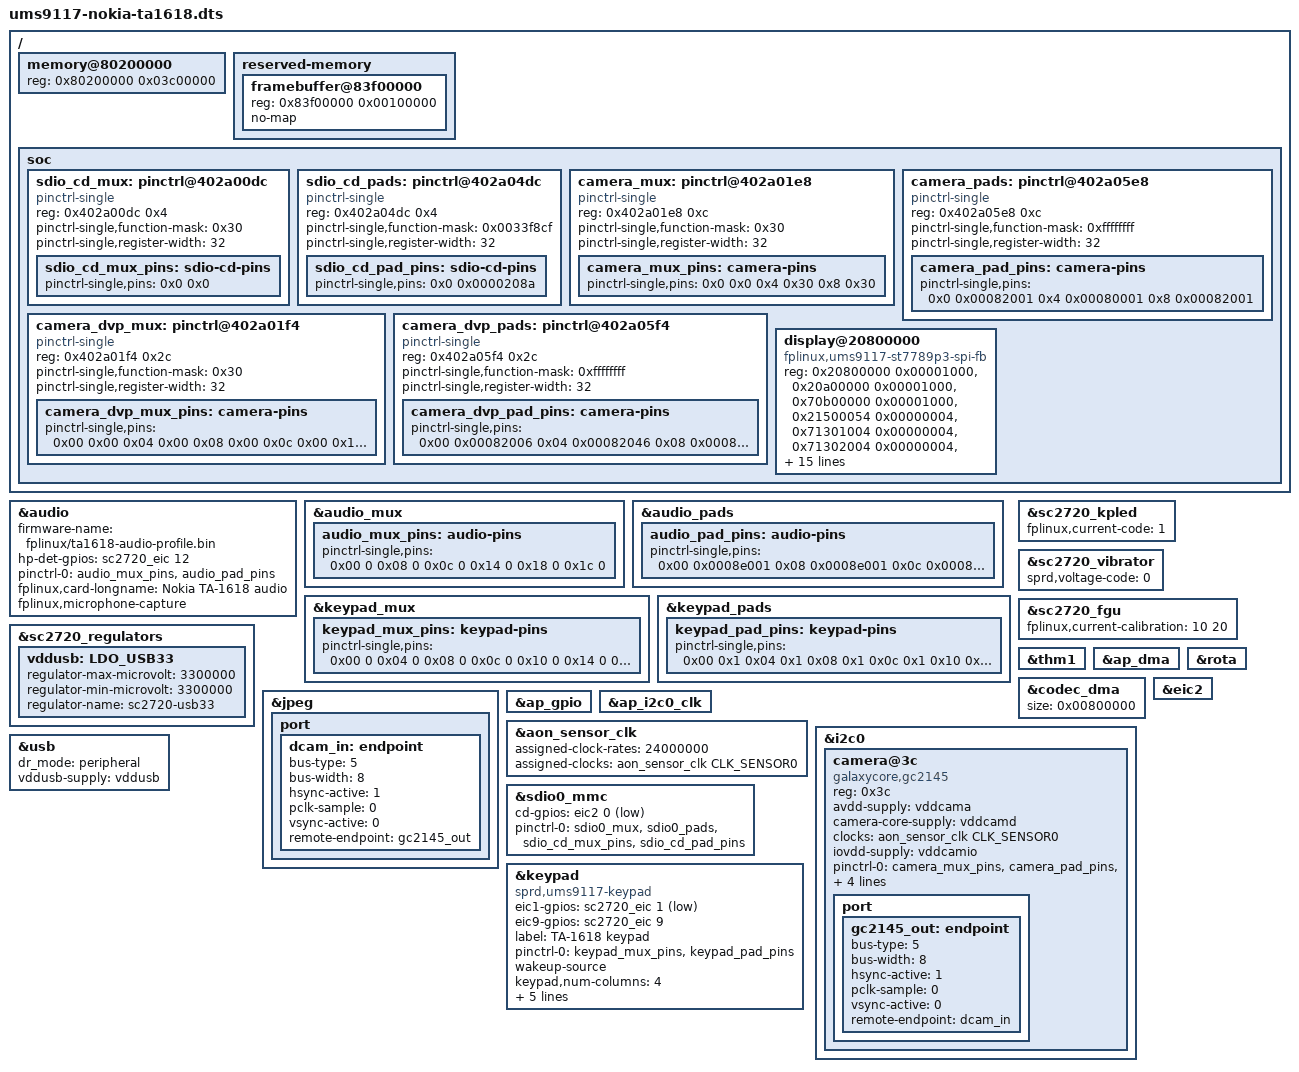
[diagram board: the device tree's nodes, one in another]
// SPDX-License-Identifier: GPL-2.0-only
/dts-v1/;

#include <dt-bindings/input/input.h>
#include <dt-bindings/input/fplinux-keypad.h>
#include <dt-bindings/gpio/gpio.h>
#include <dt-bindings/leds/common.h>
#include "ums9117.dtsi"
#include "ums9117-sc2720.dtsi"
#include "ums9117-musb-cold.dtsi"
#include "fplinux-nokia-ta1618-identity.dtsi"
#include "nokia-ta1618-nand-readonly.dtsi"
#include "nokia-ta1618-bluetooth.dtsi"

/ {
	memory@80200000 {
		device_type = "memory";
		reg = <0x80200000 0x03c00000>;
	};

	reserved-memory {
		ranges;
		#address-cells = <1>;
		#size-cells = <1>;

		framebuffer@83f00000 {
			reg = <0x83f00000 0x00100000>;
			no-map;
		};
	};

	soc {
		sdio_cd_mux: pinctrl@402a00dc {
			compatible = "pinctrl-single";
			reg = <0x402a00dc 0x4>;
			#pinctrl-cells = <1>;
			pinctrl-single,function-mask = <0x30>;
			pinctrl-single,register-width = <32>;

			sdio_cd_mux_pins: sdio-cd-pins {
				pinctrl-single,pins = <0x0 0x0>;
			};
		};

		sdio_cd_pads: pinctrl@402a04dc {
			compatible = "pinctrl-single";
			reg = <0x402a04dc 0x4>;
			#pinctrl-cells = <1>;
			pinctrl-single,function-mask = <0x0033f8cf>;
			pinctrl-single,register-width = <32>;

			sdio_cd_pad_pins: sdio-cd-pins {
				pinctrl-single,pins = <0x0 0x0000208a>;
			};
		};

		camera_mux: pinctrl@402a01e8 {
			compatible = "pinctrl-single";
			reg = <0x402a01e8 0xc>;
			#pinctrl-cells = <1>;
			pinctrl-single,function-mask = <0x30>;
			pinctrl-single,register-width = <32>;

			camera_mux_pins: camera-pins {
				pinctrl-single,pins = <0x0 0x0 0x4 0x30 0x8 0x30>;
			};
		};

		camera_pads: pinctrl@402a05e8 {
			compatible = "pinctrl-single";
			reg = <0x402a05e8 0xc>;
			#pinctrl-cells = <1>;
			pinctrl-single,function-mask = <0xffffffff>;
			pinctrl-single,register-width = <32>;

			camera_pad_pins: camera-pins {
				pinctrl-single,pins = <
					0x0 0x00082001 0x4 0x00080001
					0x8 0x00082001
				>;
			};
		};

		camera_dvp_mux: pinctrl@402a01f4 {
			compatible = "pinctrl-single";
			reg = <0x402a01f4 0x2c>;
			#pinctrl-cells = <1>;
			pinctrl-single,function-mask = <0x30>;
			pinctrl-single,register-width = <32>;

			camera_dvp_mux_pins: camera-pins {
				pinctrl-single,pins = <
					0x00 0x00 0x04 0x00 0x08 0x00 0x0c 0x00
					0x10 0x00 0x14 0x00 0x18 0x00 0x1c 0x00
					0x20 0x00 0x24 0x00 0x28 0x00
				>;
			};
		};

		camera_dvp_pads: pinctrl@402a05f4 {
			compatible = "pinctrl-single";
			reg = <0x402a05f4 0x2c>;
			#pinctrl-cells = <1>;
			pinctrl-single,function-mask = <0xffffffff>;
			pinctrl-single,register-width = <32>;

			camera_dvp_pad_pins: camera-pins {
				pinctrl-single,pins = <
					0x00 0x00082006 0x04 0x00082046
					0x08 0x00082000 0x0c 0x00082000
					0x10 0x00082000 0x14 0x00082000
					0x18 0x00082040 0x1c 0x00082040
					0x20 0x00082040 0x24 0x00082040
					0x28 0x00082000
				>;
			};
		};

		display@20800000 {
			compatible = "fplinux,ums9117-st7789p3-spi-fb";
			reg = <0x20800000 0x00001000>,
			      <0x20a00000 0x00001000>,
			      <0x70b00000 0x00001000>,
			      <0x21500054 0x00000004>,
			      <0x71301004 0x00000004>,
			      <0x71302004 0x00000004>,
			      <0x20e01000 0x00000004>,
			      <0x20e01004 0x00000004>,
			      <0x20e02004 0x00000004>,
			      <0x402a00b0 0x0000001c>,
			      <0x402a04b0 0x0000001c>;
			interrupt-names = "lcdc-done";
			interrupts = <GIC_SPI 19 IRQ_TYPE_LEVEL_HIGH>;
			memory-region = <&codec_dma>;
			reg-names = "lcdc", "lcm", "spi", "spi-clock-selector",
				    "spi-reset-set", "spi-reset-clear", "ap-ahb-gate-set",
				    "ap-ahb-reset-set", "ap-ahb-reset-clear", "pinmux",
				    "pinconf";
			sprd,aon-apb = <&aon_apb>;
			sprd,pinconf-offsets = <0 4 8 12 16 20 24>;
			sprd,pinconf-values = <
				0x00182001 0x00082046 0x00082001 0x00102004
				0x00082004 0x00102004 0x00082004
			>;
			sprd,pinmux-offsets = <0 4 8 12 16 20 24>;
			sprd,pinmux-values = <0 0 0 0 0 0 0>;
			sprd,pmic = <&sc2720_pmic>;
			sprd,wled-current-levels = <20 20 20 20>;
			sprd,wled-default-level = <15>;
		};

	};
};

#include "ums9117-ram-session.dtsi"

&audio {
	firmware-name = "fplinux/ta1618-audio-profile.bin";
	hp-det-gpios = <&sc2720_eic 12 GPIO_ACTIVE_HIGH>;
	pinctrl-0 = <&audio_mux_pins &audio_pad_pins>;
	pinctrl-names = "audio";
	fplinux,card-longname = "Nokia TA-1618 audio";
	fplinux,microphone-capture;

	status = "okay";
};

&audio_mux {
	audio_mux_pins: audio-pins {
		pinctrl-single,pins = <
			0x00 0 0x08 0 0x0c 0
			0x14 0 0x18 0 0x1c 0
		>;
	};
};

&audio_pads {
	audio_pad_pins: audio-pins {
		pinctrl-single,pins = <
			0x00 0x0008e001 0x08 0x0008e001
			0x0c 0x0008e001 0x14 0x0008e000
			0x18 0x0008e000 0x1c 0x0008e001
		>;
	};
};

&keypad_mux {
	keypad_mux_pins: keypad-pins {
		pinctrl-single,pins = <
			0x00 0 0x04 0 0x08 0 0x0c 0 0x10 0
			0x14 0 0x18 0 0x1c 0 0x20 0 0x24 0
		>;
	};
};

&keypad_pads {
	keypad_pad_pins: keypad-pins {
		pinctrl-single,pins = <
			0x00 0x1 0x04 0x1 0x08 0x1 0x0c 0x1 0x10 0x1
			0x14 0x8a 0x18 0x8a 0x1c 0x8a 0x20 0x8a 0x24 0x8a
		>;
	};
};

&sc2720_kpled {
	fplinux,current-code = <1>;
};

&sc2720_vibrator {
	sprd,voltage-code = <0>;

	status = "okay";
};

&sc2720_fgu {
	fplinux,current-calibration = <10 20>;
};

&sc2720_regulators {
	vddusb: LDO_USB33 {
		regulator-max-microvolt = <3300000>;
		regulator-min-microvolt = <3300000>;
		regulator-name = "sc2720-usb33";
	};
};

&thm1 {
	status = "okay";
};

&ap_dma {
	status = "okay";
};

&codec_dma {
	/* One 1600x1200 NV16 capture buffer needs room beside other DMA users. */
	size = <0x00800000>;
};

&rota {
	status = "okay";
};

&jpeg {
	status = "okay";
	port {
		dcam_in: endpoint {
			bus-type = <5>;
			bus-width = <8>;
			hsync-active = <1>;
			pclk-sample = <0>;
			vsync-active = <0>;
		};
	};
};

&eic2 {
	status = "okay";
};

&ap_gpio {
	status = "okay";
};

&ap_i2c0_clk {
	status = "okay";
};

&aon_sensor_clk {
	assigned-clock-rates = <24000000>;
	assigned-clocks = <&aon_sensor_clk CLK_SENSOR0>;

	status = "okay";
};

&i2c0 {
	status = "okay";

	camera@3c {
		compatible = "galaxycore,gc2145";
		reg = <0x3c>;
		avdd-supply = <&vddcama>;
		camera-core-supply = <&vddcamd>;
		clocks = <&aon_sensor_clk CLK_SENSOR0>;
		iovdd-supply = <&vddcamio>;
		pinctrl-0 = <&camera_mux_pins &camera_pad_pins
			     &camera_dvp_mux_pins &camera_dvp_pad_pins>;
		pinctrl-names = "default";
		powerdown-gpios = <&ap_gpio 101 GPIO_ACTIVE_HIGH>;
		reset-gpios = <&ap_gpio 100 GPIO_ACTIVE_LOW>;
		rotation = <270>;

		port {
			gc2145_out: endpoint {
				bus-type = <5>;
				bus-width = <8>;
				hsync-active = <1>;
				pclk-sample = <0>;
				vsync-active = <0>;
			};
		};
	};
};

&gc2145_out {
	remote-endpoint = <&dcam_in>;
};

&dcam_in {
	remote-endpoint = <&gc2145_out>;
};

&sdio0_mmc {
	cd-gpios = <&eic2 0 GPIO_ACTIVE_LOW>;
	pinctrl-0 = <&sdio0_mux &sdio0_pads
		     &sdio_cd_mux_pins &sdio_cd_pad_pins>;

	status = "okay";
};

&keypad {
	compatible = "sprd,ums9117-keypad";
	eic1-gpios = <&sc2720_eic 1 GPIO_ACTIVE_LOW>;
	eic9-gpios = <&sc2720_eic 9 GPIO_ACTIVE_HIGH>;
	label = "TA-1618 keypad";
	pinctrl-0 = <&keypad_mux_pins &keypad_pad_pins>;
	pinctrl-names = "matrix";
	wakeup-source;
	keypad,num-columns = <4>;
	keypad,num-rows = <5>;
	/* TA-1618 matrix scan map. */
	linux,keymap = <
		MATRIX_KEY(0, 0, FPLINUX_KEY_STAR)
		MATRIX_KEY(0, 1, FPLINUX_KEY_0)
		MATRIX_KEY(0, 2, FPLINUX_KEY_SOFT_LEFT)
		MATRIX_KEY(0, 3, FPLINUX_KEY_POUND)
		MATRIX_KEY(1, 0, FPLINUX_KEY_7)
		MATRIX_KEY(1, 1, FPLINUX_KEY_3)
		MATRIX_KEY(1, 2, FPLINUX_KEY_LEFT)
		MATRIX_KEY(1, 3, FPLINUX_KEY_9)
		MATRIX_KEY(2, 0, FPLINUX_KEY_1)
		MATRIX_KEY(2, 1, FPLINUX_KEY_2)
		MATRIX_KEY(2, 3, FPLINUX_KEY_6)
		MATRIX_KEY(3, 0, FPLINUX_KEY_CALL)
		MATRIX_KEY(3, 1, FPLINUX_KEY_DOWN)
		MATRIX_KEY(3, 2, FPLINUX_KEY_OK)
		MATRIX_KEY(3, 3, FPLINUX_KEY_RIGHT)
		MATRIX_KEY(4, 0, FPLINUX_KEY_4)
		MATRIX_KEY(4, 1, FPLINUX_KEY_5)
		MATRIX_KEY(4, 2, FPLINUX_KEY_UP)
		MATRIX_KEY(4, 3, FPLINUX_KEY_SOFT_RIGHT)
	>;
	sprd,eic1-keycode = <FPLINUX_KEY_POWER>;
	sprd,eic9-keycode = <FPLINUX_KEY_8>;

	status = "okay";
};

&usb {
	dr_mode = "peripheral";
	vddusb-supply = <&vddusb>;

	status = "okay";
};
